AUTOSAR XML (schema 4-3-0)
package /ComponentTypes
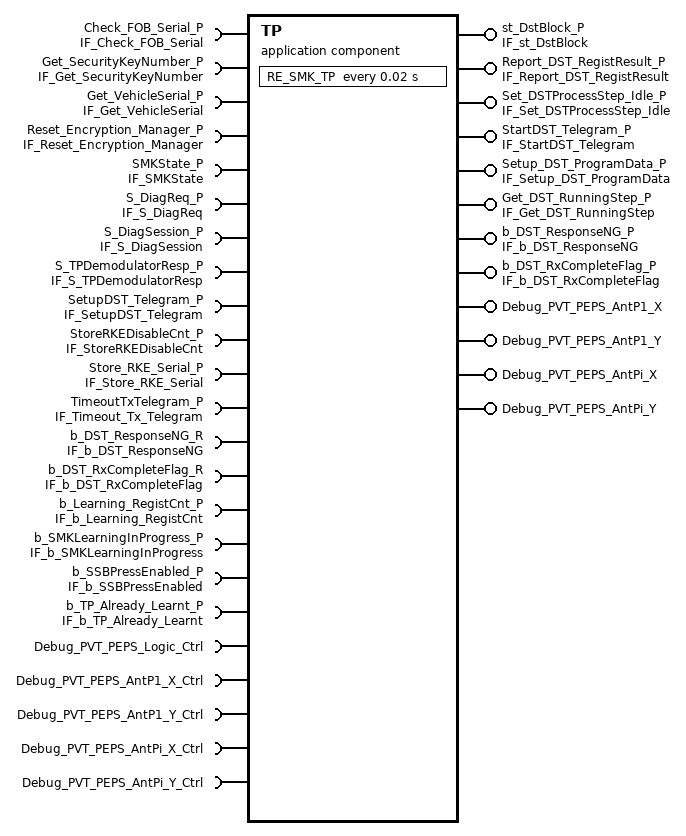
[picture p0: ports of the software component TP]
  application sw component type TP
    6 x provide port:
      st_DstBlock_P: provided-interface=IF_st_DstBlock
        provided-com-specs:
          data-element=security_key_number, init-value=[0]
          data-element=write_fob_number, init-value=0
          data-element=encryption, init-value=[0]
          data-element=challenge, init-value=[0]
          data-element=vehicle_serial, init-value=[0]
      Report_DST_RegistResult_P: server-com-spec{operation=CS, queue-length=1}, provided-interface=IF_Report_DST_RegistResult
      Set_DSTProcessStep_Idle_P: server-com-spec{operation=CS, queue-length=1}, provided-interface=IF_Set_DSTProcessStep_Idle
      StartDST_Telegram_P: server-com-spec{operation=CS, queue-length=1}, provided-interface=IF_StartDST_Telegram
      Setup_DST_ProgramData_P: server-com-spec{operation=CS, queue-length=1}, provided-interface=IF_Setup_DST_ProgramData
      Get_DST_RunningStep_P: server-com-spec{operation=CS, queue-length=1}, provided-interface=IF_Get_DST_RunningStep
    18 x require port:
      Check_FOB_Serial_P: client-com-spec=CS, required-interface=IF_Check_FOB_Serial
      Get_SecurityKeyNumber_P: client-com-spec=CS, required-interface=IF_Get_SecurityKeyNumber
      Get_VehicleSerial_P: client-com-spec=CS, required-interface=IF_Get_VehicleSerial
      Reset_Encryption_Manager_P: client-com-spec=CS, required-interface=IF_Reset_Encryption_Manager
      SMKState_P: nonqueued-receiver-com-spec{data-element=SR, filter=data-filter-type=ALWAYS, init-value=0}, required-interface=IF_SMKState
      S_DiagReq_P: nonqueued-receiver-com-spec{data-element=SR, filter=data-filter-type=ALWAYS, init-value=0}, required-interface=IF_S_DiagReq
      S_DiagSession_P: nonqueued-receiver-com-spec{data-element=SR, filter=data-filter-type=ALWAYS, init-value=0}, required-interface=IF_S_DiagSession
      S_TPDemodulatorResp_P: nonqueued-receiver-com-spec{data-element=SR, filter=data-filter-type=ALWAYS, init-value=0}, required-interface=IF_S_TPDemodulatorResp
      SetupDST_Telegram_P: client-com-spec=CS, required-interface=IF_SetupDST_Telegram
      StoreRKEDisableCnt_P: client-com-spec=CS, required-interface=IF_StoreRKEDisableCnt
      Store_RKE_Serial_P: client-com-spec=CS, required-interface=IF_Store_RKE_Serial
      TimeoutTxTelegram_P: client-com-spec=CS, required-interface=IF_Timeout_Tx_Telegram
      b_DST_ResponseNG_R: nonqueued-receiver-com-spec{data-element=SR, filter=data-filter-type=ALWAYS, init-value=0}, required-interface=IF_b_DST_ResponseNG
      b_DST_RxCompleteFlag_R: nonqueued-receiver-com-spec{data-element=SR, filter=data-filter-type=ALWAYS, init-value=0}, required-interface=IF_b_DST_RxCompleteFlag
      b_Learning_RegistCnt_P: nonqueued-receiver-com-spec{data-element=SR, filter=data-filter-type=ALWAYS, init-value=0}, required-interface=IF_b_Learning_RegistCnt
      b_SMKLearningInProgress_P: nonqueued-receiver-com-spec{data-element=SR, filter=data-filter-type=ALWAYS, init-value=0}, required-interface=IF_b_SMKLearningInProgress
      b_SSBPressEnabled_P: nonqueued-receiver-com-spec{data-element=SR, filter=data-filter-type=ALWAYS, init-value=0}, required-interface=IF_b_SSBPressEnabled
      b_TP_Already_Learnt_P: nonqueued-receiver-com-spec{data-element=SR, filter=data-filter-type=ALWAYS, init-value=0}, required-interface=IF_b_TP_Already_Learnt
    6 x provide port:
      b_DST_ResponseNG_P: nonqueued-sender-com-spec{data-element=SR, init-value=0}, provided-interface=IF_b_DST_ResponseNG
      b_DST_RxCompleteFlag_P: nonqueued-sender-com-spec{data-element=SR, init-value=0}, provided-interface=IF_b_DST_RxCompleteFlag
      Debug_PVT_PEPS_AntP1_X: nonqueued-sender-com-spec{data-element=Debug_PVT_PEPS_AntP1_X, init-value=0}, provided-interface=Debug_PVT_PEPS_AntP1_X
      Debug_PVT_PEPS_AntP1_Y: nonqueued-sender-com-spec{data-element=Debug_PVT_PEPS_AntP1_Y, init-value=0}, provided-interface=Debug_PVT_PEPS_AntP1_Y
      Debug_PVT_PEPS_AntPi_X: nonqueued-sender-com-spec{data-element=Debug_PVT_PEPS_AntPi_X, init-value=0}, provided-interface=Debug_PVT_PEPS_AntPi_X
      Debug_PVT_PEPS_AntPi_Y: nonqueued-sender-com-spec{data-element=Debug_PVT_PEPS_AntPi_Y, init-value=0}, provided-interface=Debug_PVT_PEPS_AntPi_Y
    5 x require port:
      Debug_PVT_PEPS_Logic_Ctrl: nonqueued-receiver-com-spec{data-element=Debug_PVT_PEPS_Logic_Ctrl, filter=data-filter-type=ALWAYS, init-value=0}, required-interface=Debug_PVT_PEPS_Logic_Ctrl
      Debug_PVT_PEPS_AntP1_X_Ctrl: nonqueued-receiver-com-spec{data-element=Debug_PVT_PEPS_AntP1_X_Ctrl, filter=data-filter-type=ALWAYS, init-value=0}, required-interface=Debug_PVT_PEPS_AntP1_X_Ctrl
      Debug_PVT_PEPS_AntP1_Y_Ctrl: nonqueued-receiver-com-spec{data-element=Debug_PVT_PEPS_AntP1_Y_Ctrl, filter=data-filter-type=ALWAYS, init-value=0}, required-interface=Debug_PVT_PEPS_AntP1_Y_Ctrl
      Debug_PVT_PEPS_AntPi_X_Ctrl: nonqueued-receiver-com-spec{data-element=Debug_PVT_PEPS_AntPi_X_Ctrl, filter=data-filter-type=ALWAYS, init-value=0}, required-interface=Debug_PVT_PEPS_AntPi_X_Ctrl
      Debug_PVT_PEPS_AntPi_Y_Ctrl: nonqueued-receiver-com-spec{data-element=Debug_PVT_PEPS_AntPi_Y_Ctrl, filter=data-filter-type=ALWAYS, init-value=0}, required-interface=Debug_PVT_PEPS_AntPi_Y_Ctrl
    behavior TP_InternalBehavior
      timing event TMT_RE_SMK_TP: start-on-event=RE_SMK_TP, period=0.02
      runnable RE_SMK_TP
        data-receive-point-by-arguments:
          7 x access:
            REC_b_DST_ResponseNG_R_SR: accessed-variable=b_DST_ResponseNG_R.SR
            REC_b_DST_RxCompleteFlag_R_SR: accessed-variable=b_DST_RxCompleteFlag_R.SR
            REC_Debug_PVT_PEPS_AntP1_X_Ctrl_Debug_PVT_PEPS_AntP1_X_Ctrl: accessed-variable=Debug_PVT_PEPS_AntP1_X_Ctrl.Debug_PVT_PEPS_AntP1_X_Ctrl
            REC_Debug_PVT_PEPS_AntP1_Y_Ctrl_Debug_PVT_PEPS_AntP1_Y_Ctrl: accessed-variable=Debug_PVT_PEPS_AntP1_Y_Ctrl.Debug_PVT_PEPS_AntP1_Y_Ctrl
            REC_Debug_PVT_PEPS_AntPi_X_Ctrl_Debug_PVT_PEPS_AntPi_X_Ctrl: accessed-variable=Debug_PVT_PEPS_AntPi_X_Ctrl.Debug_PVT_PEPS_AntPi_X_Ctrl
            REC_Debug_PVT_PEPS_AntPi_Y_Ctrl_Debug_PVT_PEPS_AntPi_Y_Ctrl: accessed-variable=Debug_PVT_PEPS_AntPi_Y_Ctrl.Debug_PVT_PEPS_AntPi_Y_Ctrl
            REC_Debug_PVT_PEPS_Logic_Ctrl_Debug_PVT_PEPS_Logic_Ctrl: accessed-variable=Debug_PVT_PEPS_Logic_Ctrl.Debug_PVT_PEPS_Logic_Ctrl
        data-send-points:
          11 x access:
            SEND_b_DST_ResponseNG_P_SR: accessed-variable=b_DST_ResponseNG_P.SR
            SEND_b_DST_RxCompleteFlag_P_SR: accessed-variable=b_DST_RxCompleteFlag_P.SR
            SEND_st_DstBlock_P_challenge: accessed-variable=st_DstBlock_P.challenge
            SEND_st_DstBlock_P_encryption: accessed-variable=st_DstBlock_P.encryption
            SEND_st_DstBlock_P_security_key_number: accessed-variable=st_DstBlock_P.security_key_number
            SEND_st_DstBlock_P_vehicle_serial: accessed-variable=st_DstBlock_P.vehicle_serial
            SEND_st_DstBlock_P_write_fob_number: accessed-variable=st_DstBlock_P.write_fob_number
            SEND_Debug_PVT_PEPS_AntP1_X_Debug_PVT_PEPS_AntP1_X: accessed-variable=Debug_PVT_PEPS_AntP1_X.Debug_PVT_PEPS_AntP1_X
            SEND_Debug_PVT_PEPS_AntP1_Y_Debug_PVT_PEPS_AntP1_Y: accessed-variable=Debug_PVT_PEPS_AntP1_Y.Debug_PVT_PEPS_AntP1_Y
            SEND_Debug_PVT_PEPS_AntPi_X_Debug_PVT_PEPS_AntPi_X: accessed-variable=Debug_PVT_PEPS_AntPi_X.Debug_PVT_PEPS_AntPi_X
            SEND_Debug_PVT_PEPS_AntPi_Y_Debug_PVT_PEPS_AntPi_Y: accessed-variable=Debug_PVT_PEPS_AntPi_Y.Debug_PVT_PEPS_AntPi_Y
        sync call SC_SetupDST_Telegram_P_CS: operation=SetupDST_Telegram_P.CS
        sync call SC_Timeout_Tx_Telegram_P_CS: operation=TimeoutTxTelegram_P.CS
  swc implementation TP_Implementation: behavior=TP_InternalBehavior
